# MIK32 register map
Vendor: Mikron; Series: MIK32; File version: 1.0
Registers are 32-bit, read-write, reset 0x0 unless marked. A register's access mark holds for its fields unless they carry their own. Offsets are from the block's base; [hi:lo] are bit positions; {n}, {i} and the like mark numbered series.

## CRC32 — Блок вычисления контрольных сумм
Base 0x00080400
0x00 DATA — Регистр данных
0x04 POLY — Регистр полинома
0x08 CTRL — Регистр управления
  [31:30] TOT — Перестановка битов/байтов входных данных
    0=None (Перестановка выключена); 1=Bits (Биты в байтах перестанавливаются (бит 7 с битом 0, бит 15 с битом 8, с остальными байтами так же), байты НЕ перестанавливаются;); 2=Bits_bytes (Перестанавливаются и биты, и байты); 3=Bytes (Биты в байтах НЕ перестанавливаются, байты перестанавливаются (меняются местами байты 3 и 0, 2 и 1);)
  [29:28] TOTR — Перестановки битов/байтов выходных данных
    0=None (Перестановка выключена); 1=Bits (Биты в байтах перестанавливаются (бит 7 с битом 0, бит 6 с битом 1 и т.д.; бит 15 c битом 8, бит 14 с битом 9 и т.д., с остальными байтами так же), байты НЕ перестанавливаются); 2=Bits_bytes (Перестанавливаются и биты, и байты); 3=Bytes (Биты в байтах НЕ перестанавливаются, байты перестанавливаются (меняются местами байты 3 и 0, 2 и 1);)
  [25] WAS — Назначение регистра данных
    0=Data (Записываем данные); 1=Init_data (Записываем начальное значение)
  [25] Busy ro — Бит занятости автомата. После записи в регистр данных слова для вычисления контрольной суммы бит занятости перейдет в состояние единицы через один такт после такта записи. То есть чтение регистра управления, идущее на шине AHB сразу на следующем такте после записи данных, вернет результат с нулевым (еще не обновленным) значением бита Busy
    0=Ready (Автомат закончил вычисления); 1=Busy (Автомат занят)
  [2:1] FXOR — Инверсия контрольной суммы. Некоторые протоколы подсчета контрольной суммы требуют инверсии вычисленного значения контрольной суммы (выполняется операция XOR со значением 0xFFFFFFFF)
    0=Inversion_disable (Инверсия выключена); 1=Inversion_enable (Инверсия включена (операция XOR выполняется))

## WDT — Сторожевой таймер
Base 0x00081000
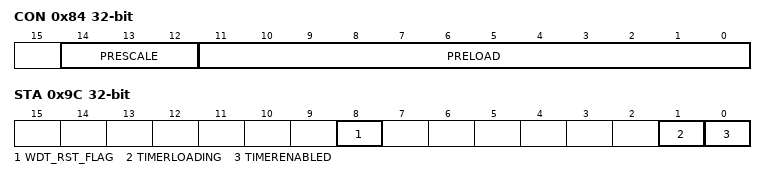
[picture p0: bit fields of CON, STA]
0x84 CON — Конфигурация
  [14:12] PRESCALE — Делитель входной частоты (Fclk) для таймера
    0=Fclk / 1; 1=Fclk / 2; 2=Fclk / 4; 3=Fclk / 16; 4=Fclk / 64; 5=Fclk / 256; 6=Fclk / 1024; 7=Fclk / 4096
  [11:0] PRELOAD — Начальное значение таймера при запуске или перезапуске (таймер считает в сторону увеличения значений)
0x9C KEY wo — Регистр ключа
0x9C STA ro — Регистр состояния
  [8] WDT_RST_FLAG — Флаг генерации сброса сторожевым таймером. Сбрасывается в 0 только при снятии и последующей подаче питания
  [1] TIMERLOADING rw — Бит перезагрузки значения
    0=Reloading_complete (Перезагрузка значения таймера в данный момент не выполняется (завершена)); 1=Reloading (Выполняется перезагрузка значения в таймере)
  [0] TIMERENABLED rw — Бит активности таймера
    0=Disable (Таймер остановлен); 1=Enable (Таймер запущен)

## TIMER32_1 — регистры модуля таймера_1
Base 0x00082800
0x00 TIM1_VALUE ro
  [31:0] TIM_VAL — текущее значение счетчика
0x04 TIM1_TOP reset 0xFFFFFFFF — максимальное значение счетной последовательности
  [31:0] TIM_TOP — максимальное значение счетчика (ограничивает счетную последоваельность сверху)
0x08 TIM1_PRESCALE — значение делителя
  [31:0] TIM_PRESCALE — Значение предварительного делителя. Предделитель вырабатывает тактовый сигнал для счета, частота которого в (TIM_PRESCALE + 1) раз меньше входной. Диапазон значений от 0 до (232 - 1)
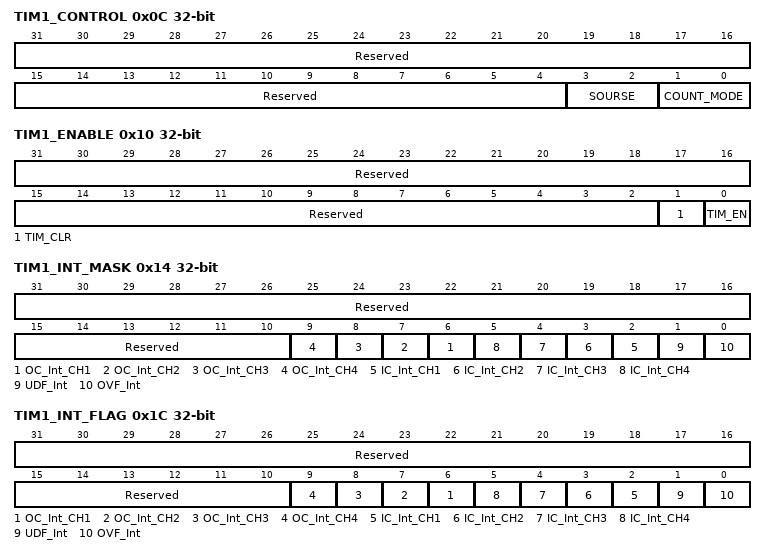
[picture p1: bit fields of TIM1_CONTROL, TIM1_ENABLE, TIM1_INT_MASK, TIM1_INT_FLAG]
0x0C TIM1_CONTROL reset not defined — Конфигурационный регистр основного таймера
  [31:4] Reserved — Зарезервировано
  [3:2] SOURSE — Выбор источника тактового сигнала для счета
    0=TIM1 (Вход модуля TIM1); 2=TIM2 (Вход модуля TIM2); 3=TIM3 (Выход предделителя)
  [1:0] COUNT_MODE — Режим счёта таймера
    0=Direct (Прямой режим); 1=Reverse (Обратный режим); 2=Bidirectional (Двунаправленный режим)
0x10 TIM1_ENABLE — Регистр включения таймера
  [31:2] Reserved — Зарезервировано
  [1] TIM_CLR write-once — Сброс (обнуление) текущего значения счетчика при записи «1»
  [0] TIM_EN — Запуск/остановка работы счетчика
    0=Disable (Счетчик выключен); 1=Enable (Счетчик работает)
0x14 TIM1_INT_MASK — Регистр маски прерываний
  [31:10] Reserved — Зарезервировано
  [n+5] OC_Int_CH{n} (n=1..4) — Маска прерывания совпадения {n} канала таймера
  [n+1] IC_Int_CH{n} (n=1..4) — Маска прерывания захвата {n} канала таймера
  [1] UDF_Int — Маска прерывания опустошения счетчика
  [0] OVF_Int — Маска прерывания по переполнению счетчика
0x18 TIM1_INT_CLEAR reset 0xFFFFFFFF — Регистр сброса флагов прерываний
0x1C TIM1_INT_FLAG ro — Регистр флагов прерываний
  [31:10] Reserved — Зарезервировано
  [n+5] OC_Int_CH{n} (n=1..4) — Статус прерывания совпадения {n} канала таймера
  [n+1] IC_Int_CH{n} (n=1..4) — Статус прерывания захвата {n} канала таймера
  [1] UDF_Int — Статус прерывания опустошения счетчика
  [0] OVF_Int — Статус прерывания по переполнению счетчика
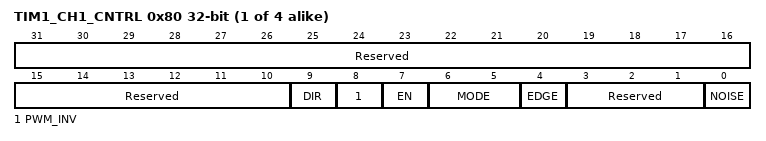
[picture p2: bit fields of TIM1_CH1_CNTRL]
{0x70+0x10*i} TIM1_CH{i}_CNTRL (i=1..4) — Конфигурационный регистр {i} канала
  [31:10] Reserved — Зарезервировано
  [9] DIR ro — Направление передачи данных. Устанавливается автоматически в зависимости от режима работы (1 - выход, 0 - вход)
    1=Output (Выход); 0=Input (Вход)
  [8] PWM_INV — Тип вывода в режиме ШИМ инвертирование
    0=Direct (Прямой (не инвертированный) выход); 1=Inverted (Инвертированный выход)
  [7] EN — Включение/выключение канала
  [6:5] MODE — Режим работы канала
    0=Reserved (Зарезервировано); 1=Compare (Режим сравнения (для timer0)); 2=Capture (Режим захвата(для timer0)); 3=PWM (ШИМ)
  [4] EDGE — Режим сигнала захвата
    0=Front (фронт); 1=Back (срез)
  [3:1] Reserved — Зарезервировано
  [0] NOISE — Управление фильтрацией входных помех на входе ic_port: 0 – фильтрация выклю-чена; 1 – фильтрация выклю-чена
    0=Enable (Фильтрация выключена); 1=Disable (Фильтрация включена)
{0x74+0x10*i} TIM1_CH{i}_OCR (i=1..4) — Значение сравнения {i} канала
  [31:0] OCR — Значение таймера в режиме сравнения
{0x78+0x10*i} TIM1_CH{i}_ICR (i=1..4) — Значение захвата {i} канала
  [31:0] ICR — Значение таймера в режиме захвата
